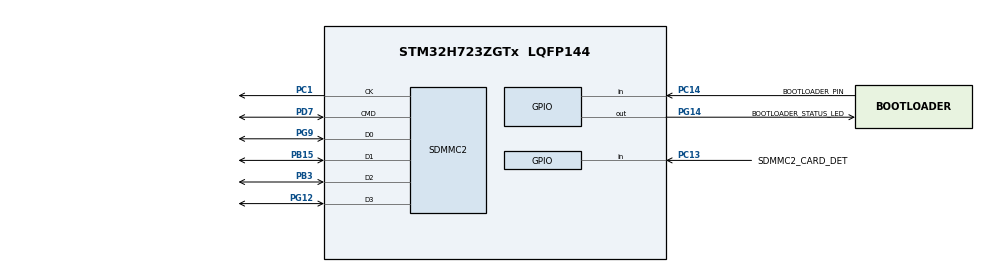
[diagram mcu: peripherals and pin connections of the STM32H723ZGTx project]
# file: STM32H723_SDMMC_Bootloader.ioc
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FATFS.BSP.number=1
FATFS._MAX_SS=4096
FATFS0.BSP.STBoard=false
FATFS0.BSP.api=Unknown
FATFS0.BSP.instance=PC13
FATFS0.BSP.ip=GPIO
FATFS0.BSP.mode=Input
FATFS0.BSP.name=Detect_SDIO
FATFS0.BSP.solution=PC13
MBEDTLS.MBEDTLS_AESNI_C=0
MBEDTLS.MBEDTLS_AES_C=0
MBEDTLS.MBEDTLS_ARC4_C=0
MBEDTLS.MBEDTLS_ASN1_PARSE_C=0
MBEDTLS.MBEDTLS_ASN1_WRITE_C=0
MBEDTLS.MBEDTLS_BASE64_C=0
MBEDTLS.MBEDTLS_BIGNUM_C=0
MBEDTLS.MBEDTLS_BLOWFISH_C=0
MBEDTLS.MBEDTLS_CAMELLIA_C=0
MBEDTLS.MBEDTLS_CERTS_C=0
MBEDTLS.MBEDTLS_CHACHA20_C=0
MBEDTLS.MBEDTLS_CIPHER_C=0
MBEDTLS.MBEDTLS_DES_C=0
MBEDTLS.MBEDTLS_DHM_C=0
MBEDTLS.MBEDTLS_ENTROPY_C=0
MBEDTLS.MBEDTLS_ERROR_C=0
MBEDTLS.MBEDTLS_HKDF_C=0
MBEDTLS.MBEDTLS_HMAC_DRBG_C=0
MBEDTLS.MBEDTLS_MD5_C=0
MBEDTLS.MBEDTLS_MD_C=1
MBEDTLS.MBEDTLS_OID_C=0
MBEDTLS.MBEDTLS_PADLOCK_C=0
MBEDTLS.MBEDTLS_PLATFORM_C=1
MBEDTLS.MBEDTLS_POLY1305_C=0
MBEDTLS.MBEDTLS_RIPEMD160_C=0
MBEDTLS.MBEDTLS_SHA1_C=0
MBEDTLS.MBEDTLS_SHA512_C=0
MBEDTLS.MBEDTLS_VERSION_C=0
MBEDTLS.MBEDTLS_XTEA_C=0
Mcu.Family=STM32H7
Mcu.Name=STM32H723ZGTx
Mcu.Package=LQFP144
NVIC.PriorityGroup=NVIC_PRIORITYGROUP_4
PA13(JTMS/SWDIO).Mode=Serial_Wire
PA13(JTMS/SWDIO).Signal=DEBUG_JTMS-SWDIO
PA14(JTCK/SWCLK).Mode=Serial_Wire
PA14(JTCK/SWCLK).Signal=DEBUG_JTCK-SWCLK
PB15.Mode=SD_4_bits_Wide_bus
PB15.Signal=SDMMC2_D1
PB3(JTDO/TRACESWO).Mode=SD_4_bits_Wide_bus
PB3(JTDO/TRACESWO).Signal=SDMMC2_D2
PC1.Mode=SD_4_bits_Wide_bus
PC1.Signal=SDMMC2_CK
PC13.GPIO_Label=SDMMC2_CARD_DET
PC13.Signal=GPIO_Input
PC14-OSC32_IN.GPIO_Label=BOOTLOADER_PIN
PC14-OSC32_IN.Signal=GPIO_Input
PD7.Mode=SD_4_bits_Wide_bus
PD7.Signal=SDMMC2_CMD
PG12.Mode=SD_4_bits_Wide_bus
PG12.Signal=SDMMC2_D3
PG14.GPIO_Label=BOOTLOADER_STATUS_LED
PG14.Signal=GPIO_Output
PG9.Mode=SD_4_bits_Wide_bus
PG9.Signal=SDMMC2_D0
PH0-OSC_IN.Mode=HSE-External-Oscillator
PH0-OSC_IN.Signal=RCC_OSC_IN
PH1-OSC_OUT.Mode=HSE-External-Oscillator
PH1-OSC_OUT.Signal=RCC_OSC_OUT
ProjectManager.HeapSize=0x200
ProjectManager.StackSize=0x400
ProjectManager.TargetToolchain=STM32CubeIDE
RCC.ADCFreq_Value=128000000
RCC.APB1Freq_Value=100000000
RCC.APB2Freq_Value=100000000
RCC.APB3Freq_Value=100000000
RCC.APB4Freq_Value=100000000
RCC.CortexFreq_Value=400000000
RCC.D1PPRE=RCC_APB3_DIV2
RCC.D2PPRE1=RCC_APB1_DIV2
RCC.D2PPRE2=RCC_APB2_DIV2
RCC.D3PPRE=RCC_APB4_DIV2
RCC.DIVM1=1
RCC.DIVM2=1
RCC.DIVN1=50
RCC.DIVN2=32
RCC.DIVP1=1
RCC.DIVR2=4
RCC.HCLKFreq_Value=200000000
RCC.HPRE=RCC_HCLK_DIV2
RCC.HSE_VALUE=8000000
RCC.PLL2FRACN=0
RCC.PLL3FRACN=0
RCC.PLLFRACN=0
RCC.PLLSourceVirtual=RCC_PLLSOURCE_HSE
RCC.SDMMC1CLockSelection=RCC_SDMMCCLKSOURCE_PLL2
RCC.SYSCLKFreq_VALUE=400000000
RCC.SYSCLKSource=RCC_SYSCLKSOURCE_PLLCLK
RCC.USBFreq_Value=200000000
VP_FATFS_VS_SDIO.Mode=SDIO
VP_MBEDTLS_VS_MBEDTLS.Mode=Enabled
VP_MEMORYMAP_VS_MEMORYMAP.Mode=CurAppReg
board=custom

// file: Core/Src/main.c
/* USER CODE BEGIN Header */
/**
 ******************************************************************************
 * @file           : main.c
 * @brief          : Main program body
 ******************************************************************************
 * @attention
 *
 * Copyright (c) 2026 STMicroelectronics.
 * All rights reserved.
 *
 * This software is licensed under terms that can be found in the LICENSE file
 * in the root directory of this software component.
 * If no LICENSE file comes with this software, it is provided AS-IS.
 *
 ******************************************************************************
 */
/* USER CODE END Header */
#include "main.h"

#include "fatfs.h"
#include "gpio.h"
#include "mbedtls.h"
#include "sdmmc.h"

/* USER CODE BEGIN Includes */

#include <stdint.h>
#include "bootloader.h"

/* USER CODE END Includes */

void SystemClock_Config(void);

int main(void)
{

	/* MCU Configuration--------------------------------------------------------*/

	/* Reset of all peripherals, Initializes the Flash interface and the Systick.
	 */
	HAL_Init();

	/* Configure the system clock */
	SystemClock_Config();

	/* Initialize all configured peripherals */
	MX_GPIO_Init();
	MX_SDMMC2_SD_Init();
	MX_FATFS_Init();
	MX_MBEDTLS_Init();
	/* USER CODE BEGIN 2 */

	GPIO_PinState boot_pin_state = HAL_GPIO_ReadPin(BOOTLOADER_PIN_GPIO_Port,
	BOOTLOADER_PIN_Pin);
	GPIO_PinState sd_card_det_pin_state = HAL_GPIO_ReadPin(
	SDMMC2_CARD_DET_GPIO_Port, SDMMC2_CARD_DET_Pin);

	if ((GPIO_PIN_SET == boot_pin_state)
			&& ((GPIO_PIN_SET == sd_card_det_pin_state)))
	{
		run_bootloader();
	}
	else
	{
		jump_to_app((FirmwareMetadata_t*) FW_START_ADDRESS);
	}

	/* USER CODE END 2 */

	/* Infinite loop */
	while (1)
	{

	}
}

void SystemClock_Config(void)
{
	RCC_OscInitTypeDef RCC_OscInitStruct =
	{ 0 };
	RCC_ClkInitTypeDef RCC_ClkInitStruct =
	{ 0 };

	/** Supply configuration update enable
	 */
	HAL_PWREx_ConfigSupply(PWR_LDO_SUPPLY);

	/** Configure the main internal regulator output voltage
	 */
	__HAL_PWR_VOLTAGESCALING_CONFIG(PWR_REGULATOR_VOLTAGE_SCALE1);

	while (!__HAL_PWR_GET_FLAG(PWR_FLAG_VOSRDY))
	{
	}

	/** Initializes the RCC Oscillators according to the specified parameters
	 * in the RCC_OscInitTypeDef structure.
	 */
	RCC_OscInitStruct.OscillatorType = RCC_OSCILLATORTYPE_HSE;
	RCC_OscInitStruct.HSEState = RCC_HSE_ON;
	RCC_OscInitStruct.PLL.PLLState = RCC_PLL_ON;
	RCC_OscInitStruct.PLL.PLLSource = RCC_PLLSOURCE_HSE;
	RCC_OscInitStruct.PLL.PLLM = 1;
	RCC_OscInitStruct.PLL.PLLN = 50;
	RCC_OscInitStruct.PLL.PLLP = 1;
	RCC_OscInitStruct.PLL.PLLQ = 2;
	RCC_OscInitStruct.PLL.PLLR = 2;
	RCC_OscInitStruct.PLL.PLLRGE = RCC_PLL1VCIRANGE_3;
	RCC_OscInitStruct.PLL.PLLVCOSEL = RCC_PLL1VCOWIDE;
	RCC_OscInitStruct.PLL.PLLFRACN = 0;
	if (HAL_RCC_OscConfig(&RCC_OscInitStruct) != HAL_OK)
	{
		Error_Handler();
	}

	/** Initializes the CPU, AHB and APB buses clocks
	 */
	RCC_ClkInitStruct.ClockType = RCC_CLOCKTYPE_HCLK | RCC_CLOCKTYPE_SYSCLK |
	RCC_CLOCKTYPE_PCLK1 | RCC_CLOCKTYPE_PCLK2 |
	RCC_CLOCKTYPE_D3PCLK1 | RCC_CLOCKTYPE_D1PCLK1;
	RCC_ClkInitStruct.SYSCLKSource = RCC_SYSCLKSOURCE_PLLCLK;
	RCC_ClkInitStruct.SYSCLKDivider = RCC_SYSCLK_DIV1;
	RCC_ClkInitStruct.AHBCLKDivider = RCC_HCLK_DIV2;
	RCC_ClkInitStruct.APB3CLKDivider = RCC_APB3_DIV2;
	RCC_ClkInitStruct.APB1CLKDivider = RCC_APB1_DIV2;
	RCC_ClkInitStruct.APB2CLKDivider = RCC_APB2_DIV2;
	RCC_ClkInitStruct.APB4CLKDivider = RCC_APB4_DIV2;

	if (HAL_RCC_ClockConfig(&RCC_ClkInitStruct, FLASH_LATENCY_2) != HAL_OK)
	{
		Error_Handler();
	}
}

void Error_Handler(void)
{
	/* USER CODE BEGIN Error_Handler_Debug */
	/* User can add his own implementation to report the HAL error return state
	 */
	__disable_irq();
	while (1)
	{
	}
	/* USER CODE END Error_Handler_Debug */
}
#ifdef USE_FULL_ASSERT
/**
 * @brief  Reports the name of the source file and the source line number
 *         where the assert_param error has occurred.
 * @param  file: pointer to the source file name
 * @param  line: assert_param error line source number
 * @retval None
 */
void assert_failed(uint8_t *file, uint32_t line) {
  /* USER CODE BEGIN 6 */
  /* User can add his own implementation to report the file name and line
     number, ex: printf("Wrong parameters value: file %s on line %d\r\n",
     file, line) */
  /* USER CODE END 6 */
}
#endif /* USE_FULL_ASSERT */
